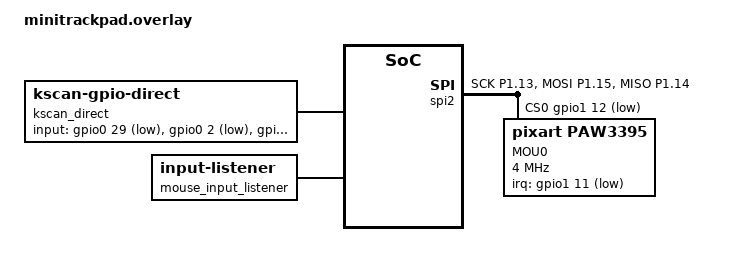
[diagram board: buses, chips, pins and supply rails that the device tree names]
/*
 * Copyright (c) 2022 The ZMK Contributors
 *
 * SPDX-License-Identifier: MIT
 */
#include <dt-bindings/zmk/matrix_transform.h>

/ {
	chosen {
		zmk,kscan = &kscan_direct;
		zmk,matrix-transform = &default_transform;
	};
    kscan_direct: kscan_direct {
        compatible = "zmk,kscan-gpio-direct";
        wakeup-source;

        input-gpios
        = <&gpio0 29 (GPIO_ACTIVE_LOW | GPIO_PULL_UP)>
        , <&gpio0 2 (GPIO_ACTIVE_LOW | GPIO_PULL_UP)>
        , <&gpio0 3 (GPIO_ACTIVE_LOW | GPIO_PULL_UP)>
        , <&gpio0 28 (GPIO_ACTIVE_LOW | GPIO_PULL_UP)>;

    };

    default_transform: keymap_transform_0 {
        compatible = "zmk,matrix-transform";
        columns = <1>;
        rows = <4>;
        map = < RC(0,0) RC(0,1) RC(0,2) RC(0,3) >;
    };

};

&pinctrl {
	spi2_default: spi2_default {
		group1 {
			psels = <NRF_PSEL(SPIM_SCK, 1, 13)>,
			<NRF_PSEL(SPIM_MOSI, 1, 15)>,
			<NRF_PSEL(SPIM_MISO, 1, 14)>;
		};
	};
	spi2_sleep: spi2_sleep {
		group1 {
			psels = <NRF_PSEL(SPIM_SCK, 1, 13)>,
			<NRF_PSEL(SPIM_MOSI, 1, 15)>,
			<NRF_PSEL(SPIM_MISO, 1, 14)>;
			low-power-enable;
		};
	};
};

#include <zephyr/dt-bindings/input/input-event-codes.h>

&spi2 {
	compatible = "nordic,nrf-spim";
  status = "okay";
	pinctrl-0 = <&spi2_default>;
	pinctrl-1 = <&spi2_sleep>;
	pinctrl-names = "default", "sleep";
	cs-gpios = <&gpio1 12 GPIO_ACTIVE_LOW>;

	pd0: pd@0 {
		compatible = "pixart,paw3395";
	  status = "okay";
		label = "MOU0";
		reg = <0>;
		spi-max-frequency = <4000000>;

		// paw3395 driver parameters
		irq-gpios = <&gpio1 11 (GPIO_ACTIVE_LOW | GPIO_PULL_UP)>;
		cpi = <600>;
		// swap-xy; /* optional */
		// invert-x; /* optional */
		// invert-y; /* optional */
		evt-type = <INPUT_EV_REL>;
		x-input-code = <INPUT_REL_X>;
		y-input-code = <INPUT_REL_Y>;
	};
};

/ {
  mouse_input_listener {
    compatible = "zmk,input-listener";
    device = <&pd0>;
  };
};
